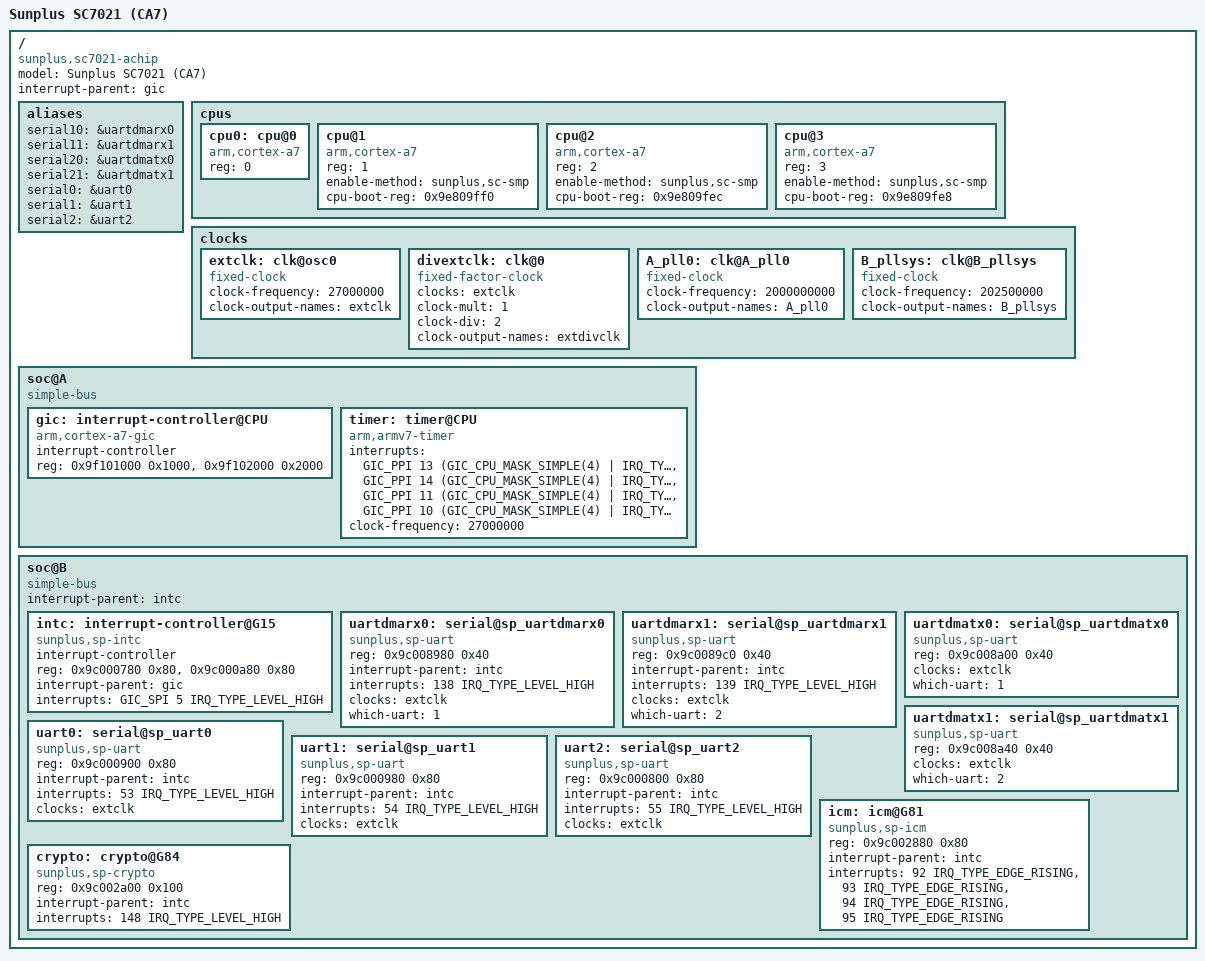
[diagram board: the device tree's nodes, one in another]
/dts-v1/;

#include "skeleton.dtsi"

#include <dt-bindings/interrupt-controller/arm-gic.h>

#define ENABLE_DMARX0
#define ENABLE_DMARX1
#define ENABLE_DMATX0
#define ENABLE_DMATX1

/ {
	model = "Sunplus SC7021 (CA7)";
	compatible = "sunplus,sc7021-achip";

	interrupt-parent = <&gic>;

	aliases {
#ifdef ENABLE_DMARX0
		serial10 = &uartdmarx0;
#endif
#ifdef ENABLE_DMARX1
		serial11 = &uartdmarx1;
#endif
#ifdef ENABLE_DMATX0
		serial20 = &uartdmatx0;
#endif
#ifdef ENABLE_DMATX1
		serial21 = &uartdmatx1;
#endif


		serial0 = &uart0;
		serial1 = &uart1;
		serial2 = &uart2;
	};

	cpus {
		#address-cells = <1>;
		#size-cells = <0>;

		cpu0: cpu@0 {
			compatible = "arm,cortex-a7";
			device_type = "cpu";
			reg = <0>;
		};
		cpu@1 {
			compatible = "arm,cortex-a7";
			device_type = "cpu";
			reg = <1>;
			enable-method = "sunplus,sc-smp";
			cpu-boot-reg = <0x9e809ff0>;
		};
		cpu@2 {
			compatible = "arm,cortex-a7";
			device_type = "cpu";
			reg = <2>;
			enable-method = "sunplus,sc-smp";
			cpu-boot-reg = <0x9e809fec>;
		};
		cpu@3 {
			compatible = "arm,cortex-a7";
			device_type = "cpu";
			reg = <3>;
			enable-method = "sunplus,sc-smp";
			cpu-boot-reg = <0x9e809fe8>;
		};
	};

	clocks {
		#address-cells = <1>;
		#size-cells = <1>;
		ranges;

		extclk: clk@osc0 {
			#clock-cells = <0>;
			compatible = "fixed-clock";
			clock-frequency = <27000000>;
			clock-output-names = "extclk";
		};

		divextclk: clk@0 {
			#clock-cells = <0>;
			compatible = "fixed-factor-clock";
			clocks  = <&extclk>;
			clock-mult = <1>;
			clock-div = <2>;
			clock-output-names = "extdivclk";
		};

		A_pll0: clk@A_pll0 {
			#clock-cells = <0>;
			compatible = "fixed-clock";
			clock-frequency = <2000000000>;
			clock-output-names = "A_pll0";
		};

		B_pllsys: clk@B_pllsys {
			#clock-cells = <0>;
			compatible = "fixed-clock";
			clock-frequency = <202500000>;
			clock-output-names = "B_pllsys";
		};
	};

	soc@A {
		compatible = "simple-bus";
		#address-cells = <1>;
		#size-cells = <1>;
		ranges;

		gic: interrupt-controller@CPU {
			compatible = "arm,cortex-a7-gic";
			interrupt-controller;
			#interrupt-cells = <3>;
			reg = <0x9f101000 0x1000>,
			      <0x9f102000 0x2000>;
		};

		timer: timer@CPU {
			compatible = "arm,armv7-timer";
			interrupts = <GIC_PPI 13 (GIC_CPU_MASK_SIMPLE(4) | IRQ_TYPE_LEVEL_LOW)>,
				     <GIC_PPI 14 (GIC_CPU_MASK_SIMPLE(4) | IRQ_TYPE_LEVEL_LOW)>,
				     <GIC_PPI 11 (GIC_CPU_MASK_SIMPLE(4) | IRQ_TYPE_LEVEL_LOW)>,
				     <GIC_PPI 10 (GIC_CPU_MASK_SIMPLE(4) | IRQ_TYPE_LEVEL_LOW)>;
			clock-frequency = <27000000>;
		};

#if 0		/* Each Cortex A-7 has its own system timer, it's not required here */
		/* This timer will be used in sp_timer_test.c */
		timer@A_G19 {
			compatible = "sunplus,sp-stc";
			reg = <0x9ec00980 0x80>;
			interrupt-parent = <&gic>;
			interrupts = <GIC_SPI 1 IRQ_TYPE_EDGE_RISING>, /* timer0 */
				     <GIC_SPI 2 IRQ_TYPE_EDGE_RISING>, /* timer1 */
				     <GIC_SPI 3 IRQ_TYPE_EDGE_RISING>, /* timer2 */
				     <GIC_SPI 4 IRQ_TYPE_EDGE_RISING>; /* timer3 */
		};
#endif

	};

	soc@B {
		compatible = "simple-bus";
		#address-cells = <1>;
		#size-cells = <1>;
		ranges;

		interrupt-parent = <&intc>;

		/* B modules */
		intc: interrupt-controller@G15 {
			compatible = "sunplus,sp-intc";
			interrupt-controller;
			#interrupt-cells = <2>;
			reg = <0x9c000780 0x80>, /* G15 */
			      <0x9c000a80 0x80>; /* G21 */
			interrupt-parent = <&gic>;
			interrupts = <GIC_SPI 5 IRQ_TYPE_LEVEL_HIGH>; /* EXT_INT0 */
		};

#ifdef ENABLE_DMARX0
		/* DMA Rx for UARTx */
		uartdmarx0: serial@sp_uartdmarx0 {
			compatible = "sunplus,sp-uart";
			reg = <0x9c008980 0x40>;
			interrupt-parent = <&intc>;
			interrupts = <138 IRQ_TYPE_LEVEL_HIGH>;
			clocks = <&extclk>;
			which-uart = <1>;
		};
#endif
#ifdef ENABLE_DMARX1
		uartdmarx1: serial@sp_uartdmarx1 {
			compatible = "sunplus,sp-uart";
			reg = <0x9c0089c0 0x40>;
			interrupt-parent = <&intc>;
			interrupts = <139 IRQ_TYPE_LEVEL_HIGH>;
			clocks = <&extclk>;
			which-uart = <2>;
		};
#endif
#ifdef ENABLE_DMATX0
		/* DMA Tx for UARTx */
		uartdmatx0: serial@sp_uartdmatx0 {
			compatible = "sunplus,sp-uart";
			reg = <0x9c008a00 0x40>;
			clocks = <&extclk>;
			which-uart = <1>;
		};
#endif
#ifdef ENABLE_DMATX1
		uartdmatx1: serial@sp_uartdmatx1 {
			compatible = "sunplus,sp-uart";
			reg = <0x9c008a40 0x40>;
			clocks = <&extclk>;
			which-uart = <2>;
		};
#endif

		uart0: serial@sp_uart0 {
			compatible = "sunplus,sp-uart";
			reg = <0x9c000900 0x80>;
			interrupt-parent = <&intc>;
			interrupts = <53 IRQ_TYPE_LEVEL_HIGH>;
			clocks = <&extclk>;
		};

		uart1: serial@sp_uart1 {
			compatible = "sunplus,sp-uart";
			reg = <0x9c000980 0x80>;
			interrupt-parent = <&intc>;
			interrupts = <54 IRQ_TYPE_LEVEL_HIGH>;
			clocks = <&extclk>;
		};

		uart2: serial@sp_uart2 {
			compatible = "sunplus,sp-uart";
			reg = <0x9c000800 0x80>;
			interrupt-parent = <&intc>;
			interrupts = <55 IRQ_TYPE_LEVEL_HIGH>;
			clocks = <&extclk>;
		};

		icm: icm@G81 {
			compatible = "sunplus,sp-icm";
			reg = <0x9c002880 0x80>;
			interrupt-parent = <&intc>;
			interrupts = <92 IRQ_TYPE_EDGE_RISING>, /* icm0 */
					<93 IRQ_TYPE_EDGE_RISING>, /* icm1 */
					<94 IRQ_TYPE_EDGE_RISING>, /* icm2 */
					<95 IRQ_TYPE_EDGE_RISING>; /* icm3 */
		};

		crypto: crypto@G84 {
			compatible = "sunplus,sp-crypto";
			reg = <0x9c002a00 0x100>; /* G84 - G85 */
			interrupt-parent = <&intc>;
			interrupts = <148 IRQ_TYPE_LEVEL_HIGH>;
		};

/* Timer tests: */
/* 1. Enable device tree for timers. */
/* 2. Enable sp_timer_test in drivers/misc/Makefile */
#if 0
		sp_tmr_tst0: sp_tmr_tst@9c000600 {
			compatible = "sunplus,sp-tmr-tst";
			reg = <0x9c000600 0x80>;
			interrupt-parent = <&intc>;
			interrupts =
				<151 IRQ_TYPE_EDGE_RISING>, /* timer0 */
				<152 IRQ_TYPE_EDGE_RISING>, /* timer1 */
				<153 IRQ_TYPE_EDGE_RISING>, /* timer2 */
				<154 IRQ_TYPE_EDGE_RISING>; /* timer3 */
		};

		sp_tmr_tst1: sp_tmr_tst@9c003000 {
			compatible = "sunplus,sp-tmr-tst";
			reg = <0x9c003000 0x80>;
			interrupt-parent = <&intc>;
			interrupts =
				<155 IRQ_TYPE_EDGE_RISING>, /* timer0 */
				<156 IRQ_TYPE_EDGE_RISING>, /* timer1 */
				<157 IRQ_TYPE_EDGE_RISING>, /* timer2 */
				<158 IRQ_TYPE_EDGE_RISING>; /* timer3 */
		};

		sp_tmr_tst2: sp_tmr_tst@9c003080 {
			compatible = "sunplus,sp-tmr-tst";
			reg = <0x9c003080 0x80>;
			interrupt-parent = <&intc>;
			interrupts =
				<159 IRQ_TYPE_EDGE_RISING>, /* timer0 */
				<160 IRQ_TYPE_EDGE_RISING>, /* timer1 */
				<161 IRQ_TYPE_EDGE_RISING>, /* timer2 */
				<162 IRQ_TYPE_EDGE_RISING>; /* timer3 */
		};

		sp_tmr_tst3: sp_tmr_tst@9c003180 {
			compatible = "sunplus,sp-tmr-tst";
			reg = <0x9c003180 0x80>;
			interrupt-parent = <&intc>;
			interrupts =
				<164 IRQ_TYPE_EDGE_RISING>, /* timer0 */
				<165 IRQ_TYPE_EDGE_RISING>, /* timer1 */
				<166 IRQ_TYPE_EDGE_RISING>, /* timer2 */
				<167 IRQ_TYPE_EDGE_RISING>; /* timer3 */
		};
#endif
	};
};
